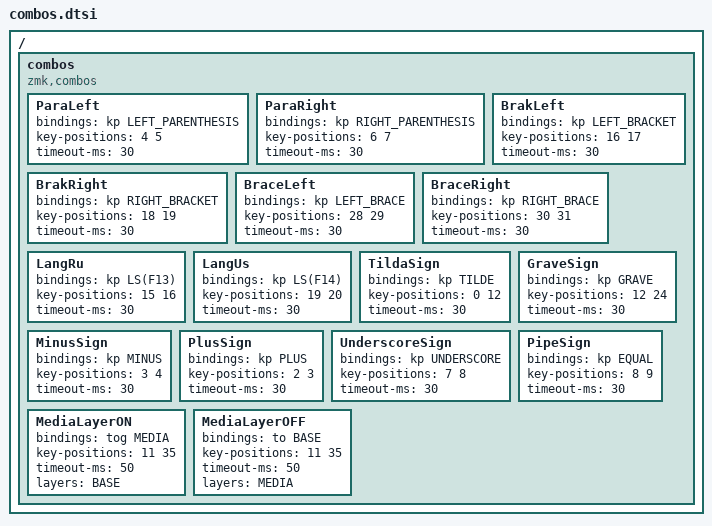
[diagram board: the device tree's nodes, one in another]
#include "layers.dtsi"

/ {
    combos {
        compatible = "zmk,combos";

        ParaLeft {
            bindings = <&kp LEFT_PARENTHESIS>;
            key-positions = <4 5>;
            timeout-ms = <30>;
        };

        ParaRight {
            bindings = <&kp RIGHT_PARENTHESIS>;
            key-positions = <6 7>;
            timeout-ms = <30>;
        };

        BrakLeft {
            bindings = <&kp LEFT_BRACKET>;
            key-positions = <16 17>;
            timeout-ms = <30>;
        };

        BrakRight {
            bindings = <&kp RIGHT_BRACKET>;
            key-positions = <18 19>;
            timeout-ms = <30>;
        };

        BraceLeft {
            bindings = <&kp LEFT_BRACE>;
            key-positions = <28 29>;
            timeout-ms = <30>;
        };

        BraceRight {
            bindings = <&kp RIGHT_BRACE>;
            key-positions = <30 31>;
            timeout-ms = <30>;
        };
		
		LangRu {
            bindings = <&kp LS(F13)>;
            key-positions = <15 16>;
            timeout-ms = <30>;
        };

        LangUs {
            bindings = <&kp LS(F14)>;
            key-positions = <19 20>;
            timeout-ms = <30>;
        };

        //DoubleQuote {
        //    bindings = <&kp DOUBLE_QUOTES>;
        //    key-positions = <15 16>;
        //    timeout-ms = <30>;
        //};

        //SingleQuote {
        //    bindings = <&kp APOSTROPHE>;
        //    key-positions = <19 20>;
        //    timeout-ms = <30>;
        //};

        TildaSign {
            bindings = <&kp TILDE>;
            key-positions = <0 12>;
            timeout-ms = <30>;
        };

        GraveSign {
            bindings = <&kp GRAVE>;
            key-positions = <12 24>;
            timeout-ms = <30>;
        };

        MinusSign {
            bindings = <&kp MINUS>;
            key-positions = <3 4>;
            timeout-ms = <30>;
        };

        PlusSign {
            bindings = <&kp PLUS>;
            key-positions = <2 3>;
            timeout-ms = <30>;
        };

        UnderscoreSign {
            bindings = <&kp UNDERSCORE>;
            key-positions = <7 8>;
            timeout-ms = <30>;
        };

        PipeSign {
            bindings = <&kp EQUAL>;
            key-positions = <8 9>;
            timeout-ms = <30>;
        };
		
		MediaLayerON {
            bindings = <&tog MEDIA>;
            key-positions = <11 35>;
            timeout-ms = <50>;
			layers = <BASE>;
        };
		
		MediaLayerOFF {
            bindings = <&to BASE>;
            key-positions = <11 35>;
            timeout-ms = <50>;
			layers = <MEDIA>;
        };
    };
};
